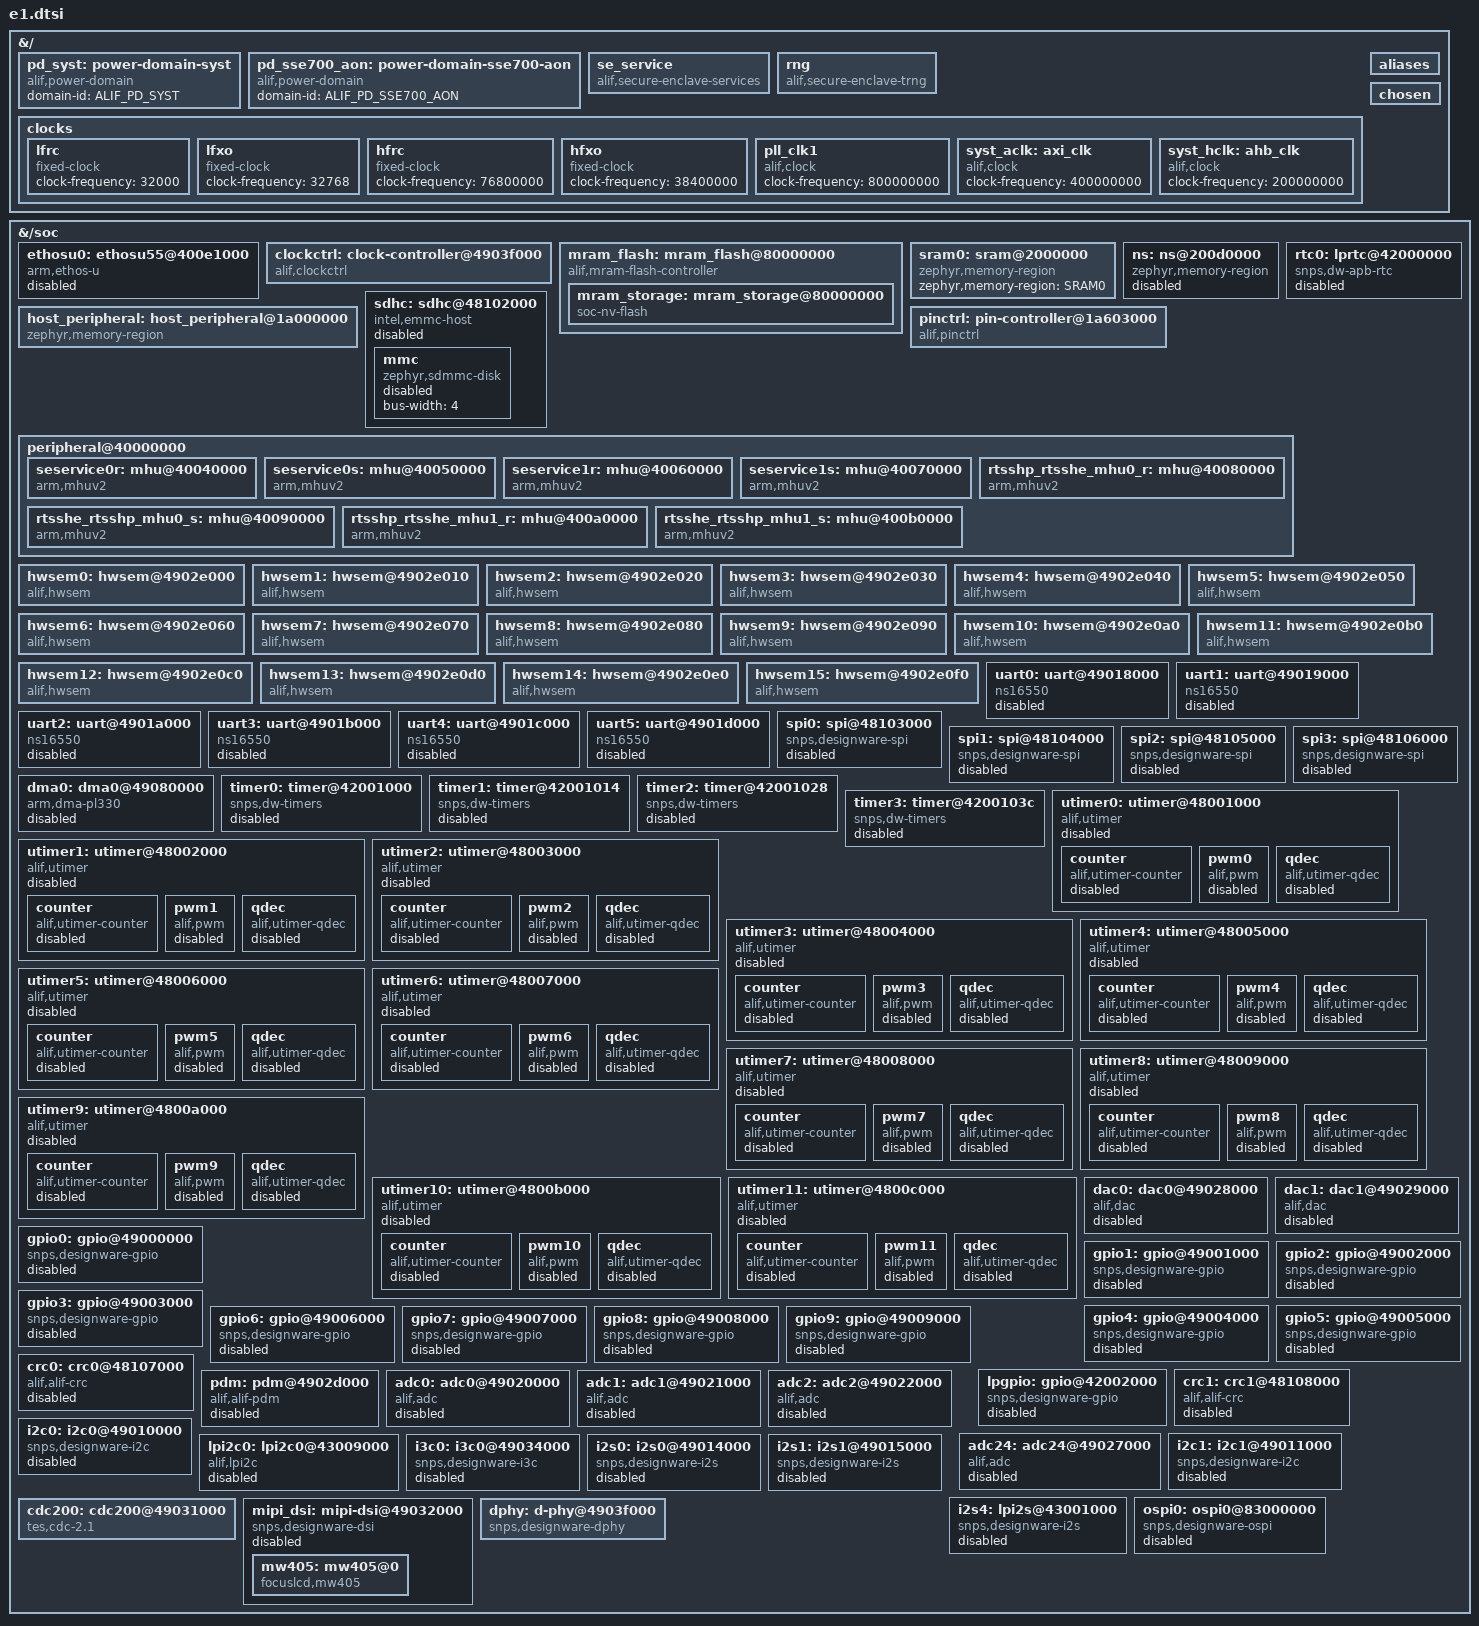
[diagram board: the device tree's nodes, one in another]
/* Copyright (c) 2025 Alif Semiconductor
 *
 * SPDX-License-Identifier: Apache-2.0
 */

#include <arm/armv8.1-m.dtsi>
#include <mem.h>
#include <zephyr/dt-bindings/gpio/gpio.h>
#include <zephyr/dt-bindings/timer/alif_utimer.h>
#include <zephyr/dt-bindings/adc/adc_alif.h>
#include <zephyr/dt-bindings/pwm/pwm.h>
#include <zephyr/dt-bindings/i2c/i2c.h>
#include <alif/common/alif_common.dtsi>
#include <zephyr/dt-bindings/mipi_dsi/mipi_dsi.h>
#include <zephyr/dt-bindings/power-domain/alif_power_domain.h>

&{/} {
	/* Individual power domain devices - one per domain */
	pd_syst: power-domain-syst {
		compatible = "alif,power-domain";
		domain-id = <ALIF_PD_SYST>;
		#power-domain-cells = <0>;
		status = "okay";
	};

	pd_sse700_aon: power-domain-sse700-aon {
		compatible = "alif,power-domain";
		domain-id = <ALIF_PD_SSE700_AON>;
		#power-domain-cells = <0>;
		status = "okay";
	};
};

&{/soc} {

	ethosu0: ethosu55@400e1000 {
		compatible = "arm,ethos-u";
		reg = <0x400e1000 0x1000>;
		interrupts = <55 0>;
		interrupt-parent = <&nvic>;
		secure-enable;
		privilege-enable;
		status = "disabled";
	};

	clockctrl: clock-controller@4903f000 {
		compatible = "alif,clockctrl";
		reg = <0x4903F000 0xB0
			0x4902F000 0xBC
			0x1A604000 0x44
			0x1A609000 0x14
			0x43007000 0x2C
			0x400F0000 0x14>;
		reg-names = "clkctl_per_mst",
			    "clkctl_per_slv",
			    "aon",
			    "vbat",
			    "m55he_cfg",
			    "m55hp_cfg";
		#clock-cells = <1>;
		status = "okay";
	};

	mram_flash: mram_flash@80000000 {
		compatible = "alif,mram-flash-controller";
		#address-cells = <1>;
		#size-cells = <1>;

		mram_storage: mram_storage@80000000 {
			compatible = "soc-nv-flash";
			erase-block-size = <1024>;
			write-block-size = <16>;
		};
	};

	sram0: sram@2000000 {
		compatible = "zephyr,memory-region","mmio-sram";
		zephyr,memory-region = "SRAM0";
	};

	ns: ns@200d0000 {
		compatible = "zephyr,memory-region";
		/* Ensemble TGU Block Size(16KB) Aligned always */
		reg = <0x200d0000 DT_SIZE_K(176)>;
		zephyr,memory-region = "NON_SECURE0";
		status = "disabled";
	};

	host_peripheral: host_peripheral@1a000000 {
		compatible = "zephyr,memory-region";
		zephyr,memory-region = "HOST_PERIPHERAL";
		reg = <0x1A000000 DT_SIZE_K(16384)>;
	};

	pinctrl: pin-controller@1a603000 {
		compatible = "alif,pinctrl";
		reg = <0x1A603000 0x00001000>, <0x42007000 0x00001000>;
		reg-names = "pinctrl", "lpgpio_pinctrl";
	};

	rtc0: lprtc@42000000 {
		compatible = "snps,dw-apb-rtc";
		reg = <0x42000000 0x1000>;
		interrupts = <58 ALIF_DEFAULT_IRQ_PRIORITY>;
		clock-frequency = <32768>;
		prescaler = <0>;
		load-value = <0>;
		status = "disabled";
	};

	sdhc: sdhc@48102000 {
		compatible = "intel,emmc-host";
		reg = <0x48102000 0xF70>;
		interrupt-parent = <&nvic>;
		interrupts = <102 ALIF_DEFAULT_IRQ_PRIORITY>;
		max-bus-freq = <25000000U>;
		min-bus-freq = <400000>;
		power-delay-ms = <500>;
		pinctrl-0 = <&pinctrl_sdmmc>;
		pinctrl-names = "default";
		mmc {
			compatible = "zephyr,sdmmc-disk";
			bus-width = <4>;
			status = "disabled";
		};
		status = "disabled";
	};

	peripheral@40000000 {
		#address-cells = < 0x1 >;
		#size-cells = < 0x1 >;
		ranges = < 0x0 0x40000000 0x2000000 >;

		seservice0r: mhu@40040000 {
			compatible = "arm,mhuv2";
			reg = < 0x40040000 0x1000 >;
			interrupts = < 37 ALIF_DEFAULT_IRQ_PRIORITY >;
			interrupt-names = "rx";
		};

		seservice0s: mhu@40050000 {
			compatible = "arm,mhuv2";
			reg = < 0x40050000 0x1000 >;
			interrupts = < 38 ALIF_DEFAULT_IRQ_PRIORITY >;
			interrupt-names = "tx";
		};

		seservice1r: mhu@40060000 {
			compatible = "arm,mhuv2";
			reg = < 0x40060000 0x1000 >;
			interrupts = < 39 ALIF_DEFAULT_IRQ_PRIORITY >;
			interrupt-names = "rx";
		};

		seservice1s: mhu@40070000 {
			compatible = "arm,mhuv2";
			reg = < 0x40070000 0x1000 >;
			interrupts = < 40 ALIF_DEFAULT_IRQ_PRIORITY >;
			interrupt-names = "tx";
		};

		rtsshp_rtsshe_mhu0_r: mhu@40080000 {
			compatible = "arm,mhuv2";
			reg = < 0x40080000 0x1000 >;
			interrupts = < 41 ALIF_DEFAULT_IRQ_PRIORITY >;
			interrupt-names = "rx";
		};

		rtsshe_rtsshp_mhu0_s: mhu@40090000 {
			compatible = "arm,mhuv2";
			reg = < 0x40090000 0x1000 >;
			interrupts = < 42 ALIF_DEFAULT_IRQ_PRIORITY >;
			interrupt-names = "tx";
		};

		rtsshp_rtsshe_mhu1_r: mhu@400a0000 {
			compatible = "arm,mhuv2";
			reg = < 0x400A0000 0x1000 >;
			interrupts = < 43 ALIF_DEFAULT_IRQ_PRIORITY >;
			interrupt-names = "rx";
		};

		rtsshe_rtsshp_mhu1_s: mhu@400b0000 {
			compatible = "arm,mhuv2";
			reg = < 0x400B0000 0x1000 >;
			interrupts = < 44 ALIF_DEFAULT_IRQ_PRIORITY >;
			interrupt-names = "tx";
		};
	};

	hwsem0: hwsem@4902e000 {
		compatible = "alif,hwsem";
		reg = <0x4902E000 0x10>;
		interrupts = < 105 ALIF_DEFAULT_IRQ_PRIORITY >;
	};

	hwsem1: hwsem@4902e010 {
		compatible = "alif,hwsem";
		reg = <0x4902E010 0x10>;
		interrupts = < 106 ALIF_DEFAULT_IRQ_PRIORITY >;
	};

	hwsem2: hwsem@4902e020 {
		compatible = "alif,hwsem";
		reg = <0x4902E020 0x10>;
		interrupts = < 107 ALIF_DEFAULT_IRQ_PRIORITY >;
	};

	hwsem3: hwsem@4902e030 {
		compatible = "alif,hwsem";
		reg = <0x4902E030 0x10>;
		interrupts = < 108 ALIF_DEFAULT_IRQ_PRIORITY >;
	};

	hwsem4: hwsem@4902e040 {
		compatible = "alif,hwsem";
		reg = <0x4902E040 0x10>;
		interrupts = < 109 ALIF_DEFAULT_IRQ_PRIORITY >;
	};

	hwsem5: hwsem@4902e050 {
		compatible = "alif,hwsem";
		reg = <0x4902E050 0x10>;
		interrupts = < 110 ALIF_DEFAULT_IRQ_PRIORITY >;
	};

	hwsem6: hwsem@4902e060 {
		compatible = "alif,hwsem";
		reg = <0x4902E060 0x10>;
		interrupts = < 111 ALIF_DEFAULT_IRQ_PRIORITY >;
	};

	hwsem7: hwsem@4902e070 {
		compatible = "alif,hwsem";
		reg = <0x4902E070 0x10>;
		interrupts = < 112 ALIF_DEFAULT_IRQ_PRIORITY >;
	};

	hwsem8: hwsem@4902e080 {
		compatible = "alif,hwsem";
		reg = <0x4902E080 0x10>;
		interrupts = < 113 ALIF_DEFAULT_IRQ_PRIORITY >;
	};

	hwsem9: hwsem@4902e090 {
		compatible = "alif,hwsem";
		reg = <0x4902E090 0x10>;
		interrupts = < 114 ALIF_DEFAULT_IRQ_PRIORITY >;
	};

	hwsem10: hwsem@4902e0a0 {
		compatible = "alif,hwsem";
		reg = <0x4902E0A0 0x10>;
		interrupts = < 115 ALIF_DEFAULT_IRQ_PRIORITY >;
	};

	hwsem11: hwsem@4902e0b0 {
		compatible = "alif,hwsem";
		reg = <0x4902E0B0 0x10>;
		interrupts = < 116 ALIF_DEFAULT_IRQ_PRIORITY >;
	};

	hwsem12: hwsem@4902e0c0 {
		compatible = "alif,hwsem";
		reg = <0x4902E0C0 0x10>;
		interrupts = < 117 ALIF_DEFAULT_IRQ_PRIORITY >;
	};

	hwsem13: hwsem@4902e0d0 {
		compatible = "alif,hwsem";
		reg = <0x4902E0D0 0x10>;
		interrupts = < 118 ALIF_DEFAULT_IRQ_PRIORITY >;
	};

	hwsem14: hwsem@4902e0e0 {
		compatible = "alif,hwsem";
		reg = <0x4902E0E0 0x10>;
		interrupts = < 119 ALIF_DEFAULT_IRQ_PRIORITY >;
	};

	hwsem15: hwsem@4902e0f0 {
		compatible = "alif,hwsem";
		reg = <0x4902E0F0 0x10>;
		interrupts = < 120 ALIF_DEFAULT_IRQ_PRIORITY >;
	};

	uart0: uart@49018000 {
		compatible = "ns16550";
		reg = <0x49018000 0x100>;
		clocks = <&clockctrl ALIF_UART0_SYST_PCLK>;
		interrupts = <124 ALIF_DEFAULT_IRQ_PRIORITY>;
		power-domains = <&pd_syst>;
		reg-shift = <2>;
		current-speed = <115200>;
		dlf = <4>;
		pinctrl-0 = <&pinctrl_uart0>;
		pinctrl-1 = <&pinctrl_uart0_sleep>;
		pinctrl-names = "default", "sleep";
		fifo-size = <32>;
		status = "disabled";
	};

	uart1: uart@49019000 {
		compatible = "ns16550";
		reg = <0x49019000 0x100>;
		clocks = <&clockctrl ALIF_UART1_SYST_PCLK>;
		interrupts = <125 ALIF_DEFAULT_IRQ_PRIORITY>;
		power-domains = <&pd_syst>;
		reg-shift = <2>;
		current-speed = <115200>;
		dlf = <4>;
		pinctrl-0 = <&pinctrl_uart1>;
		pinctrl-1 = <&pinctrl_uart1_sleep>;
		pinctrl-names = "default", "sleep";
		fifo-size = <32>;
		status = "disabled";
	};

	uart2: uart@4901a000 {
		compatible = "ns16550";
		reg = <0x4901a000 0x100>;
		clocks = <&clockctrl ALIF_UART2_SYST_PCLK>;
		interrupts = <126 ALIF_DEFAULT_IRQ_PRIORITY>;
		power-domains = <&pd_syst>;
		reg-shift = <2>;
		current-speed = <115200>;
		dlf = <4>;
		pinctrl-0 = <&pinctrl_uart2>;
		pinctrl-1 = <&pinctrl_uart2_sleep>;
		pinctrl-names = "default", "sleep";
		fifo-size = <32>;
		status = "disabled";
	};

	uart3: uart@4901b000 {
		compatible = "ns16550";
		reg = <0x4901b000 0x100>;
		clocks = <&clockctrl ALIF_UART3_SYST_PCLK>;
		interrupts = <127 ALIF_DEFAULT_IRQ_PRIORITY>;
		power-domains = <&pd_syst>;
		reg-shift = <2>;
		current-speed = <115200>;
		dlf = <4>;
		pinctrl-0 = <&pinctrl_uart3>;
		pinctrl-1 = <&pinctrl_uart3_sleep>;
		pinctrl-names = "default", "sleep";
		fifo-size = <32>;
		status = "disabled";
	};

	uart4: uart@4901c000 {
		compatible = "ns16550";
		reg = <0x4901c000 0x100>;
		clocks = <&clockctrl ALIF_UART4_SYST_PCLK>;
		interrupts = <128 ALIF_DEFAULT_IRQ_PRIORITY>;
		power-domains = <&pd_syst>;
		reg-shift = <2>;
		current-speed = <115200>;
		dlf = <4>;
		pinctrl-0 = <&pinctrl_uart4>;
		pinctrl-1 = <&pinctrl_uart4_sleep>;
		pinctrl-names = "default", "sleep";
		fifo-size = <32>;
		status = "disabled";
	};

	uart5: uart@4901d000 {
		compatible = "ns16550";
		reg = <0x4901d000 0x100>;
		clocks = <&clockctrl ALIF_UART5_SYST_PCLK>;
		interrupts = <129 ALIF_DEFAULT_IRQ_PRIORITY>;
		power-domains = <&pd_syst>;
		reg-shift = <2>;
		current-speed = <115200>;
		dlf = <4>;
		pinctrl-0 = <&pinctrl_uart5>;
		pinctrl-1 = <&pinctrl_uart5_sleep>;
		pinctrl-names = "default", "sleep";
		fifo-size = <32>;
		status = "disabled";
	};

	spi0: spi@48103000 {
		dwc-ssi;
		compatible = "snps,designware-spi";
		#address-cells = <1>;
		#size-cells = <0>;
		pinctrl-0 = < &pinctrl_spi0 >;
		pinctrl-names = "default";
		reg = <0x48103000 0x1000>;
		interrupt-parent = <&nvic>;
		interrupts = <137 ALIF_DEFAULT_IRQ_PRIORITY>;
		clocks = <&syst_hclk>;
		fifo-depth = <16>;
		max-xfer-size = <32>;
		rx-delay = <4>;
		status = "disabled";
	};

	spi1: spi@48104000 {
		dwc-ssi;
		compatible = "snps,designware-spi";
		#address-cells = <1>;
		#size-cells = <0>;
		pinctrl-0 = < &pinctrl_spi1 >;
		pinctrl-names = "default";
		reg = <0x48104000 0x1000>;
		interrupt-parent = <&nvic>;
		interrupts = <138 ALIF_DEFAULT_IRQ_PRIORITY>;
		clocks = <&syst_hclk>;
		fifo-depth = <16>;
		max-xfer-size = <32>;
		rx-delay = <4>;
		status = "disabled";
	};

	spi2: spi@48105000 {
		dwc-ssi;
		compatible = "snps,designware-spi";
		#address-cells = <1>;
		#size-cells = <0>;
		pinctrl-0 = < &pinctrl_spi2 >;
		pinctrl-names = "default";
		reg = <0x48105000 0x1000>;
		interrupt-parent = <&nvic>;
		interrupts = <139 ALIF_DEFAULT_IRQ_PRIORITY>;
		clocks = <&syst_hclk>;
		fifo-depth = <16>;
		max-xfer-size = <32>;
		rx-delay = <4>;
		status = "disabled";
	};

	spi3: spi@48106000 {
		dwc-ssi;
		compatible = "snps,designware-spi";
		#address-cells = <1>;
		#size-cells = <0>;
		pinctrl-0 = < &pinctrl_spi3 >;
		pinctrl-names = "default";
		reg = <0x48106000 0x1000>;
		interrupt-parent = <&nvic>;
		interrupts = <140 ALIF_DEFAULT_IRQ_PRIORITY>;
		clocks = <&syst_hclk>;
		fifo-depth = <16>;
		max-xfer-size = <32>;
		rx-delay = <4>;
		status = "disabled";
	};

	dma0: dma0@49080000 {
		compatible = "arm,dma-pl330";
		reg = <0x49080000 0x1000>;
		reg-names = "pl330_regs";
		dma-channels = <4>;
		#dma-cells = <2>;
		interrupt-parent = <&nvic>;
		interrupts = <299 ALIF_DEFAULT_IRQ_PRIORITY>,
			     <300 ALIF_DEFAULT_IRQ_PRIORITY>,
			     <301 ALIF_DEFAULT_IRQ_PRIORITY>,
			     <302 ALIF_DEFAULT_IRQ_PRIORITY>,
			     <331 ALIF_DEFAULT_IRQ_PRIORITY>;
		interrupt-names = "channel0", "channel1",
						  "channel2", "channel3",
						  "abort";
		status = "disabled";
	};
	timer0: timer@42001000 {
		compatible = "snps,dw-timers";
		reg = <0x42001000 0x14>;
		interrupts = <60 ALIF_DEFAULT_IRQ_PRIORITY>;
		clocks = <&clockctrl ALIF_LPTIMER0_S32K_CLK>;
		status = "disabled";
	};

	timer1: timer@42001014 {
		compatible = "snps,dw-timers";
		reg = <0x42001014 0x14>;
		interrupts = <61 ALIF_DEFAULT_IRQ_PRIORITY>;
		clocks = <&clockctrl ALIF_LPTIMER1_S32K_CLK>;
		status = "disabled";
	};

	timer2: timer@42001028 {
		compatible = "snps,dw-timers";
		reg = <0x42001028 0x14>;
		interrupts = <62 ALIF_DEFAULT_IRQ_PRIORITY>;
		clocks = <&clockctrl ALIF_LPTIMER2_S32K_CLK>;
		status = "disabled";
	};

	timer3: timer@4200103c {
		compatible = "snps,dw-timers";
		reg = <0x4200103C 0x14>;
		interrupts = <63 ALIF_DEFAULT_IRQ_PRIORITY>;
		clocks = <&clockctrl ALIF_LPTIMER3_S32K_CLK>;
		status = "disabled";
	};

	utimer0: utimer@48001000 {
		compatible = "alif,utimer";
		reg = <0x48001000 0x1000 0x48000000 0x24>;
		reg-names = "timer", "global";
		interrupts = <377 ALIF_DEFAULT_IRQ_PRIORITY>,
			     <378 ALIF_DEFAULT_IRQ_PRIORITY>,
			     <379 ALIF_DEFAULT_IRQ_PRIORITY>,
			     <380 ALIF_DEFAULT_IRQ_PRIORITY>,
			     <381 ALIF_DEFAULT_IRQ_PRIORITY>,
			     <382 ALIF_DEFAULT_IRQ_PRIORITY>,
			     <383 ALIF_DEFAULT_IRQ_PRIORITY>,
			     <384 ALIF_DEFAULT_IRQ_PRIORITY>;
		interrupt-names = "comp_capt_a", "comp_capt_b",
				"comp_a_buf1", "comp_a_buf2", "comp_b_buf1",
				"comp_b_buf2", "underflow", "overflow";
		timer-id = <0>;
		clocks = <&clockctrl ALIF_UTIMER_CLK>;
		counter-direction = < ALIF_UTIMER_COUNTER_DIRECTION_UP >;
		status = "disabled";

		counter {
			compatible = "alif,utimer-counter";
			status = "disabled";
		};

		pwm0 {
			compatible = "alif,pwm";
			#pwm-cells = <3>;
			status = "disabled";
		};

		qdec {
			compatible = "alif,utimer-qdec";
			counts-per-revolution = <1000>;
			input-filter-enable;
			filter-prescaler = <16>;
			filter-taps = <1>;
			status = "disabled";
		};
	};

	utimer1: utimer@48002000 {
		compatible = "alif,utimer";
		reg = <0x48002000 0x1000 0x48000000 0x24>;
		reg-names = "timer", "global";
		interrupts = <385 ALIF_DEFAULT_IRQ_PRIORITY>,
			     <386 ALIF_DEFAULT_IRQ_PRIORITY>,
			     <387 ALIF_DEFAULT_IRQ_PRIORITY>,
			     <388 ALIF_DEFAULT_IRQ_PRIORITY>,
			     <389 ALIF_DEFAULT_IRQ_PRIORITY>,
			     <390 ALIF_DEFAULT_IRQ_PRIORITY>,
			     <391 ALIF_DEFAULT_IRQ_PRIORITY>,
			     <392 ALIF_DEFAULT_IRQ_PRIORITY>;
		interrupt-names = "comp_capt_a", "comp_capt_b",
				"comp_a_buf1", "comp_a_buf2", "comp_b_buf1",
				"comp_b_buf2", "underflow", "overflow";
		timer-id = <1>;
		clocks = <&clockctrl ALIF_UTIMER_CLK>;
		counter-direction = < ALIF_UTIMER_COUNTER_DIRECTION_UP >;
		status = "disabled";

		counter {
			compatible = "alif,utimer-counter";
			status = "disabled";
		};

		pwm1 {
			compatible = "alif,pwm";
			#pwm-cells = <3>;
			status = "disabled";
		};

		qdec {
			compatible = "alif,utimer-qdec";
			counts-per-revolution = <1000>;
			input-filter-enable;
			filter-prescaler = <16>;
			filter-taps = <1>;
			status = "disabled";
		};
	};

	utimer2: utimer@48003000 {
		compatible = "alif,utimer";
		reg = <0x48003000 0x1000 0x48000000 0x24>;
		reg-names = "timer", "global";
		interrupts = <393 ALIF_DEFAULT_IRQ_PRIORITY>,
			     <394 ALIF_DEFAULT_IRQ_PRIORITY>,
			     <395 ALIF_DEFAULT_IRQ_PRIORITY>,
			     <396 ALIF_DEFAULT_IRQ_PRIORITY>,
			     <397 ALIF_DEFAULT_IRQ_PRIORITY>,
			     <398 ALIF_DEFAULT_IRQ_PRIORITY>,
			     <399 ALIF_DEFAULT_IRQ_PRIORITY>,
			     <400 ALIF_DEFAULT_IRQ_PRIORITY>;
		interrupt-names = "comp_capt_a", "comp_capt_b",
				"comp_a_buf1", "comp_a_buf2", "comp_b_buf1",
				"comp_b_buf2", "underflow", "overflow";
		timer-id = <2>;
		clocks = <&clockctrl ALIF_UTIMER_CLK>;
		counter-direction = < ALIF_UTIMER_COUNTER_DIRECTION_UP >;
		status = "disabled";

		counter {
			compatible = "alif,utimer-counter";
			status = "disabled";
		};

		pwm2 {
			compatible = "alif,pwm";
			#pwm-cells = <3>;
			status = "disabled";
		};

		qdec {
			compatible = "alif,utimer-qdec";
			counts-per-revolution = <1000>;
			input-filter-enable;
			filter-prescaler = <16>;
			filter-taps = <1>;
			status = "disabled";
		};
	};

	utimer3: utimer@48004000 {
		compatible = "alif,utimer";
		reg = <0x48004000 0x1000 0x48000000 0x24>;
		reg-names = "timer", "global";
		interrupts = <401 ALIF_DEFAULT_IRQ_PRIORITY>,
			     <402 ALIF_DEFAULT_IRQ_PRIORITY>,
			     <403 ALIF_DEFAULT_IRQ_PRIORITY>,
			     <404 ALIF_DEFAULT_IRQ_PRIORITY>,
			     <405 ALIF_DEFAULT_IRQ_PRIORITY>,
			     <406 ALIF_DEFAULT_IRQ_PRIORITY>,
			     <407 ALIF_DEFAULT_IRQ_PRIORITY>,
			     <408 ALIF_DEFAULT_IRQ_PRIORITY>;
		interrupt-names = "comp_capt_a", "comp_capt_b",
				"comp_a_buf1", "comp_a_buf2", "comp_b_buf1",
				"comp_b_buf2", "underflow", "overflow";
		timer-id = <3>;
		clocks = <&clockctrl ALIF_UTIMER_CLK>;
		counter-direction = < ALIF_UTIMER_COUNTER_DIRECTION_UP >;
		status = "disabled";

		counter {
			compatible = "alif,utimer-counter";
			status = "disabled";
		};

		pwm3 {
			compatible = "alif,pwm";
			#pwm-cells = <3>;
			status = "disabled";
		};

		qdec {
			compatible = "alif,utimer-qdec";
			counts-per-revolution = <1000>;
			input-filter-enable;
			filter-prescaler = <16>;
			filter-taps = <1>;
			status = "disabled";
		};
	};

	utimer4: utimer@48005000 {
		compatible = "alif,utimer";
		reg = <0x48005000 0x1000 0x48000000 0x24>;
		reg-names = "timer", "global";
		interrupts = <409 ALIF_DEFAULT_IRQ_PRIORITY>,
			     <410 ALIF_DEFAULT_IRQ_PRIORITY>,
			     <411 ALIF_DEFAULT_IRQ_PRIORITY>,
			     <412 ALIF_DEFAULT_IRQ_PRIORITY>,
			     <413 ALIF_DEFAULT_IRQ_PRIORITY>,
			     <414 ALIF_DEFAULT_IRQ_PRIORITY>,
			     <415 ALIF_DEFAULT_IRQ_PRIORITY>,
			     <416 ALIF_DEFAULT_IRQ_PRIORITY>;
		interrupt-names = "comp_capt_a", "comp_capt_b",
				"comp_a_buf1", "comp_a_buf2", "comp_b_buf1",
				"comp_b_buf2", "underflow", "overflow";
		timer-id = <4>;
		clocks = <&clockctrl ALIF_UTIMER_CLK>;
		counter-direction = < ALIF_UTIMER_COUNTER_DIRECTION_UP >;
		status = "disabled";

		counter {
			compatible = "alif,utimer-counter";
			status = "disabled";
		};

		pwm4 {
			compatible = "alif,pwm";
			#pwm-cells = <3>;
			status = "disabled";
		};

		qdec {
			compatible = "alif,utimer-qdec";
			counts-per-revolution = <1000>;
			input-filter-enable;
			filter-prescaler = <16>;
			filter-taps = <1>;
			status = "disabled";
		};
	};

	utimer5: utimer@48006000 {
		compatible = "alif,utimer";
		reg = <0x48006000 0x1000 0x48000000 0x24>;
		reg-names = "timer", "global";
		interrupts = <417 ALIF_DEFAULT_IRQ_PRIORITY>,
			     <418 ALIF_DEFAULT_IRQ_PRIORITY>,
			     <419 ALIF_DEFAULT_IRQ_PRIORITY>,
			     <420 ALIF_DEFAULT_IRQ_PRIORITY>,
			     <421 ALIF_DEFAULT_IRQ_PRIORITY>,
			     <422 ALIF_DEFAULT_IRQ_PRIORITY>,
			     <423 ALIF_DEFAULT_IRQ_PRIORITY>,
			     <424 ALIF_DEFAULT_IRQ_PRIORITY>;
		interrupt-names = "comp_capt_a", "comp_capt_b",
				"comp_a_buf1", "comp_a_buf2", "comp_b_buf1",
				"comp_b_buf2", "underflow", "overflow";
		timer-id = <5>;
		clocks = <&clockctrl ALIF_UTIMER_CLK>;
		counter-direction = < ALIF_UTIMER_COUNTER_DIRECTION_UP >;
		status = "disabled";

		counter {
			compatible = "alif,utimer-counter";
			status = "disabled";
		};

		pwm5 {
			compatible = "alif,pwm";
			#pwm-cells = <3>;
			status = "disabled";
		};

		qdec {
			compatible = "alif,utimer-qdec";
			counts-per-revolution = <1000>;
			input-filter-enable;
			filter-prescaler = <16>;
			filter-taps = <1>;
			status = "disabled";
		};
	};

	utimer6: utimer@48007000 {
		compatible = "alif,utimer";
		reg = <0x48007000 0x1000 0x48000000 0x24>;
		reg-names = "timer", "global";
		interrupts = <425 ALIF_DEFAULT_IRQ_PRIORITY>,
			     <426 ALIF_DEFAULT_IRQ_PRIORITY>,
			     <427 ALIF_DEFAULT_IRQ_PRIORITY>,
			     <428 ALIF_DEFAULT_IRQ_PRIORITY>,
			     <429 ALIF_DEFAULT_IRQ_PRIORITY>,
			     <430 ALIF_DEFAULT_IRQ_PRIORITY>,
			     <431 ALIF_DEFAULT_IRQ_PRIORITY>,
			     <432 ALIF_DEFAULT_IRQ_PRIORITY>;
		interrupt-names = "comp_capt_a", "comp_capt_b",
				"comp_a_buf1", "comp_a_buf2", "comp_b_buf1",
				"comp_b_buf2", "underflow", "overflow";
		timer-id = <6>;
		clocks = <&clockctrl ALIF_UTIMER_CLK>;
		counter-direction = < ALIF_UTIMER_COUNTER_DIRECTION_UP >;
		status = "disabled";

		counter {
			compatible = "alif,utimer-counter";
			status = "disabled";
		};

		pwm6 {
			compatible = "alif,pwm";
			#pwm-cells = <3>;
			status = "disabled";
		};

		qdec {
			compatible = "alif,utimer-qdec";
			counts-per-revolution = <1000>;
			input-filter-enable;
			filter-prescaler = <16>;
			filter-taps = <1>;
			status = "disabled";
		};
	};

	utimer7: utimer@48008000 {
		compatible = "alif,utimer";
		reg = <0x48008000 0x1000 0x48000000 0x24>;
		reg-names = "timer", "global";
		interrupts = <433 ALIF_DEFAULT_IRQ_PRIORITY>,
			     <434 ALIF_DEFAULT_IRQ_PRIORITY>,
			     <435 ALIF_DEFAULT_IRQ_PRIORITY>,
			     <436 ALIF_DEFAULT_IRQ_PRIORITY>,
			     <437 ALIF_DEFAULT_IRQ_PRIORITY>,
			     <438 ALIF_DEFAULT_IRQ_PRIORITY>,
			     <439 ALIF_DEFAULT_IRQ_PRIORITY>,
			     <440 ALIF_DEFAULT_IRQ_PRIORITY>;
		interrupt-names = "comp_capt_a", "comp_capt_b",
				"comp_a_buf1", "comp_a_buf2", "comp_b_buf1",
				"comp_b_buf2", "underflow", "overflow";
		timer-id = <7>;
		clocks = <&clockctrl ALIF_UTIMER_CLK>;
		counter-direction = < ALIF_UTIMER_COUNTER_DIRECTION_UP >;
		status = "disabled";

		counter {
			compatible = "alif,utimer-counter";
			status = "disabled";
		};

		pwm7 {
			compatible = "alif,pwm";
			#pwm-cells = <3>;
			status = "disabled";
		};

		qdec {
			compatible = "alif,utimer-qdec";
			counts-per-revolution = <1000>;
			input-filter-enable;
			filter-prescaler = <16>;
			filter-taps = <1>;
			status = "disabled";
		};
	};

	utimer8: utimer@48009000 {
		compatible = "alif,utimer";
		reg = <0x48009000 0x1000 0x48000000 0x24>;
		reg-names = "timer", "global";
		interrupts = <441 ALIF_DEFAULT_IRQ_PRIORITY>,
			     <442 ALIF_DEFAULT_IRQ_PRIORITY>,
			     <443 ALIF_DEFAULT_IRQ_PRIORITY>,
			     <444 ALIF_DEFAULT_IRQ_PRIORITY>,
			     <445 ALIF_DEFAULT_IRQ_PRIORITY>,
			     <446 ALIF_DEFAULT_IRQ_PRIORITY>,
			     <447 ALIF_DEFAULT_IRQ_PRIORITY>,
			     <448 ALIF_DEFAULT_IRQ_PRIORITY>;
		interrupt-names = "comp_capt_a", "comp_capt_b",
				"comp_a_buf1", "comp_a_buf2", "comp_b_buf1",
				"comp_b_buf2", "underflow", "overflow";
		timer-id = <8>;
		clocks = <&clockctrl ALIF_UTIMER_CLK>;
		counter-direction = < ALIF_UTIMER_COUNTER_DIRECTION_UP >;
		status = "disabled";

		counter {
			compatible = "alif,utimer-counter";
			status = "disabled";
		};

		pwm8 {
			compatible = "alif,pwm";
			#pwm-cells = <3>;
			status = "disabled";
		};

		qdec {
			compatible = "alif,utimer-qdec";
			counts-per-revolution = <1000>;
			input-filter-enable;
			filter-prescaler = <16>;
			filter-taps = <1>;
			status = "disabled";
		};
	};

	utimer9: utimer@4800a000 {
		compatible = "alif,utimer";
		reg = <0x4800A000 0x1000 0x48000000 0x24>;
		reg-names = "timer", "global";
		interrupts = <449 ALIF_DEFAULT_IRQ_PRIORITY>,
			     <450 ALIF_DEFAULT_IRQ_PRIORITY>,
			     <451 ALIF_DEFAULT_IRQ_PRIORITY>,
			     <452 ALIF_DEFAULT_IRQ_PRIORITY>,
			     <453 ALIF_DEFAULT_IRQ_PRIORITY>,
			     <454 ALIF_DEFAULT_IRQ_PRIORITY>,
			     <455 ALIF_DEFAULT_IRQ_PRIORITY>,
			     <456 ALIF_DEFAULT_IRQ_PRIORITY>;
		interrupt-names = "comp_capt_a", "comp_capt_b",
				"comp_a_buf1", "comp_a_buf2", "comp_b_buf1",
				"comp_b_buf2", "underflow", "overflow";
		timer-id = <9>;
		clocks = <&clockctrl ALIF_UTIMER_CLK>;
		counter-direction = < ALIF_UTIMER_COUNTER_DIRECTION_UP >;
		status = "disabled";

		counter {
			compatible = "alif,utimer-counter";
			status = "disabled";
		};

		pwm9 {
			compatible = "alif,pwm";
			#pwm-cells = <3>;
			status = "disabled";
		};

		qdec {
			compatible = "alif,utimer-qdec";
			counts-per-revolution = <1000>;
			input-filter-enable;
			filter-prescaler = <16>;
			filter-taps = <1>;
			status = "disabled";
		};
	};

	utimer10: utimer@4800b000 {
		compatible = "alif,utimer";
		reg = <0x4800B000 0x1000 0x48000000 0x24>;
		reg-names = "timer", "global";
		interrupts = <457 ALIF_DEFAULT_IRQ_PRIORITY>,
			     <458 ALIF_DEFAULT_IRQ_PRIORITY>,
			     <459 ALIF_DEFAULT_IRQ_PRIORITY>,
			     <460 ALIF_DEFAULT_IRQ_PRIORITY>,
			     <461 ALIF_DEFAULT_IRQ_PRIORITY>,
			     <462 ALIF_DEFAULT_IRQ_PRIORITY>,
			     <463 ALIF_DEFAULT_IRQ_PRIORITY>,
			     <464 ALIF_DEFAULT_IRQ_PRIORITY>;
		interrupt-names = "comp_capt_a", "comp_capt_b",
				"comp_a_buf1", "comp_a_buf2", "comp_b_buf1",
				"comp_b_buf2", "underflow", "overflow";
		timer-id = <10>;
		clocks = <&clockctrl ALIF_UTIMER_CLK>;
		counter-direction = < ALIF_UTIMER_COUNTER_DIRECTION_UP >;
		status = "disabled";

		counter {
			compatible = "alif,utimer-counter";
			status = "disabled";
		};

		pwm10 {
			compatible = "alif,pwm";
			#pwm-cells = <3>;
			status = "disabled";
		};

		qdec {
			compatible = "alif,utimer-qdec";
			counts-per-revolution = <1000>;
			input-filter-enable;
			filter-prescaler = <16>;
			filter-taps = <1>;
			status = "disabled";
		};
	};

	utimer11: utimer@4800c000 {
		compatible = "alif,utimer";
		reg = <0x4800C000 0x1000 0x48000000 0x24>;
		reg-names = "timer", "global";
		interrupts = <465 ALIF_DEFAULT_IRQ_PRIORITY>,
			     <466 ALIF_DEFAULT_IRQ_PRIORITY>,
			     <467 ALIF_DEFAULT_IRQ_PRIORITY>,
			     <468 ALIF_DEFAULT_IRQ_PRIORITY>,
			     <469 ALIF_DEFAULT_IRQ_PRIORITY>,
			     <470 ALIF_DEFAULT_IRQ_PRIORITY>,
			     <471 ALIF_DEFAULT_IRQ_PRIORITY>,
			     <472 ALIF_DEFAULT_IRQ_PRIORITY>;
		interrupt-names = "comp_capt_a", "comp_capt_b",
				"comp_a_buf1", "comp_a_buf2", "comp_b_buf1",
				"comp_b_buf2", "underflow", "overflow";
		timer-id = <11>;
		clocks = <&clockctrl ALIF_UTIMER_CLK>;
		counter-direction = < ALIF_UTIMER_COUNTER_DIRECTION_UP >;
		status = "disabled";

		counter {
			compatible = "alif,utimer-counter";
			status = "disabled";
		};

		pwm11 {
			compatible = "alif,pwm";
			#pwm-cells = <3>;
			status = "disabled";
		};

		qdec {
			compatible = "alif,utimer-qdec";
			counts-per-revolution = <1000>;
			input-filter-enable;
			filter-prescaler = <16>;
			filter-taps = <1>;
			status = "disabled";
		};
	};

	dac0: dac0@49028000 {
		compatible = "alif,dac";
		reg = <0x49028000 0x1000>,
			<0x49023000 0x100>,
			<0x1A60A000 0x100>,
			<0x4902B000 0x100>;
		reg-names = "dac_reg","cmp_reg","vbat_reg","adc_vref";
		pinctrl-names = "default";
		pinctrl-0 = <&pinctrl_dac0>;
		output_current = "DAC_1200UA_OUT_CUR";
		capacitance = "DAC_8PF_CAPACITANCE";
		status = "disabled";
	};

	dac1: dac1@49029000 {
		compatible = "alif,dac";
		reg = <0x49029000 0x1000>,
			<0x49023000 0x100>,
			<0x1A60A000 0x100>,
			<0x4902B000 0x100>;
		reg-names = "dac_reg","cmp_reg","vbat_reg","adc_vref";
		pinctrl-names = "default";
		pinctrl-0 = <&pinctrl_dac1>;
		output_current = "DAC_1200UA_OUT_CUR";
		capacitance = "DAC_8PF_CAPACITANCE";
		status = "disabled";
	};

	gpio0: gpio@49000000 {
		compatible = "snps,designware-gpio";
		reg = <0x49000000 0x1000>;
		ngpios = <8>;
		interrupts = <179 ALIF_DEFAULT_IRQ_PRIORITY>,
			     <180 ALIF_DEFAULT_IRQ_PRIORITY>,
			     <181 ALIF_DEFAULT_IRQ_PRIORITY>,
			     <182 ALIF_DEFAULT_IRQ_PRIORITY>,
			     <183 ALIF_DEFAULT_IRQ_PRIORITY>,
			     <184 ALIF_DEFAULT_IRQ_PRIORITY>,
			     <185 ALIF_DEFAULT_IRQ_PRIORITY>,
			     <186 ALIF_DEFAULT_IRQ_PRIORITY>;
		pinctrl-0 = < &pinctrl_gpio0 >;
		pinctrl-names = "default";
		gpio-controller;
		#gpio-cells = <2>;
		status = "disabled";
	};

	gpio1: gpio@49001000 {
		compatible = "snps,designware-gpio";
		reg = <0x49001000 0x1000>;
		ngpios = <8>;
		interrupts = <187 ALIF_DEFAULT_IRQ_PRIORITY>,
			     <188 ALIF_DEFAULT_IRQ_PRIORITY>,
			     <189 ALIF_DEFAULT_IRQ_PRIORITY>,
			     <190 ALIF_DEFAULT_IRQ_PRIORITY>,
			     <191 ALIF_DEFAULT_IRQ_PRIORITY>,
			     <192 ALIF_DEFAULT_IRQ_PRIORITY>,
			     <193 ALIF_DEFAULT_IRQ_PRIORITY>,
			     <194 ALIF_DEFAULT_IRQ_PRIORITY>;
		pinctrl-0 = < &pinctrl_gpio1 >;
		pinctrl-names = "default";
		gpio-controller;
		#gpio-cells = <2>;
		status = "disabled";
	};

	gpio2: gpio@49002000 {
		compatible = "snps,designware-gpio";
		reg = <0x49002000 0x1000>;
		ngpios = <8>;
		interrupts = <195 ALIF_DEFAULT_IRQ_PRIORITY>,
			     <196 ALIF_DEFAULT_IRQ_PRIORITY>,
			     <197 ALIF_DEFAULT_IRQ_PRIORITY>,
			     <198 ALIF_DEFAULT_IRQ_PRIORITY>,
			     <199 ALIF_DEFAULT_IRQ_PRIORITY>,
			     <200 ALIF_DEFAULT_IRQ_PRIORITY>,
			     <201 ALIF_DEFAULT_IRQ_PRIORITY>,
			     <202 ALIF_DEFAULT_IRQ_PRIORITY>;
		pinctrl-0 = < &pinctrl_gpio2 >;
		pinctrl-names = "default";
		gpio-controller;
		#gpio-cells = <2>;
		status = "disabled";
	};

	gpio3: gpio@49003000 {
		compatible = "snps,designware-gpio";
		reg = <0x49003000 0x1000>;
		ngpios = <8>;
		interrupts = <203 ALIF_DEFAULT_IRQ_PRIORITY>,
			     <204 ALIF_DEFAULT_IRQ_PRIORITY>,
			     <205 ALIF_DEFAULT_IRQ_PRIORITY>,
			     <206 ALIF_DEFAULT_IRQ_PRIORITY>,
			     <207 ALIF_DEFAULT_IRQ_PRIORITY>,
			     <208 ALIF_DEFAULT_IRQ_PRIORITY>,
			     <209 ALIF_DEFAULT_IRQ_PRIORITY>,
			     <210 ALIF_DEFAULT_IRQ_PRIORITY>;
		pinctrl-0 = < &pinctrl_gpio3 >;
		pinctrl-names = "default";
		gpio-controller;
		#gpio-cells = <2>;
		status = "disabled";
	};

	gpio4: gpio@49004000 {
		compatible = "snps,designware-gpio";
		reg = <0x49004000 0x1000>;
		ngpios = <8>;
		interrupts = <211 ALIF_DEFAULT_IRQ_PRIORITY>,
			     <212 ALIF_DEFAULT_IRQ_PRIORITY>,
			     <213 ALIF_DEFAULT_IRQ_PRIORITY>,
			     <214 ALIF_DEFAULT_IRQ_PRIORITY>,
			     <215 ALIF_DEFAULT_IRQ_PRIORITY>,
			     <216 ALIF_DEFAULT_IRQ_PRIORITY>,
			     <217 ALIF_DEFAULT_IRQ_PRIORITY>,
			     <218 ALIF_DEFAULT_IRQ_PRIORITY>;
		pinctrl-0 = < &pinctrl_gpio4 >;
		pinctrl-names = "default";
		gpio-controller;
		#gpio-cells = <2>;
		status = "disabled";
	};

	gpio5: gpio@49005000 {
		compatible = "snps,designware-gpio";
		reg = <0x49005000 0x1000>;
		ngpios = <8>;
		interrupts = <219 ALIF_DEFAULT_IRQ_PRIORITY>,
			     <220 ALIF_DEFAULT_IRQ_PRIORITY>,
			     <221 ALIF_DEFAULT_IRQ_PRIORITY>,
			     <222 ALIF_DEFAULT_IRQ_PRIORITY>,
			     <223 ALIF_DEFAULT_IRQ_PRIORITY>,
			     <224 ALIF_DEFAULT_IRQ_PRIORITY>,
			     <225 ALIF_DEFAULT_IRQ_PRIORITY>,
			     <226 ALIF_DEFAULT_IRQ_PRIORITY>;
		pinctrl-0 = < &pinctrl_gpio5 >;
		pinctrl-names = "default";
		gpio-controller;
		#gpio-cells = <2>;
		status = "disabled";
	};

	gpio6: gpio@49006000 {
		compatible = "snps,designware-gpio";
		reg = <0x49006000 0x1000>;
		ngpios = <8>;
		interrupts = <227 ALIF_DEFAULT_IRQ_PRIORITY>,
			     <228 ALIF_DEFAULT_IRQ_PRIORITY>,
			     <229 ALIF_DEFAULT_IRQ_PRIORITY>,
			     <230 ALIF_DEFAULT_IRQ_PRIORITY>,
			     <231 ALIF_DEFAULT_IRQ_PRIORITY>,
			     <232 ALIF_DEFAULT_IRQ_PRIORITY>,
			     <233 ALIF_DEFAULT_IRQ_PRIORITY>,
			     <234 ALIF_DEFAULT_IRQ_PRIORITY>;
		pinctrl-0 = < &pinctrl_gpio6 >;
		pinctrl-names = "default";
		gpio-controller;
		#gpio-cells = <2>;
		status = "disabled";
	};

	gpio7: gpio@49007000 {
		compatible = "snps,designware-gpio";
		reg = <0x49007000 0x1000>;
		ngpios = <8>;
		interrupts = <235 ALIF_DEFAULT_IRQ_PRIORITY>,
			     <236 ALIF_DEFAULT_IRQ_PRIORITY>,
			     <237 ALIF_DEFAULT_IRQ_PRIORITY>,
			     <238 ALIF_DEFAULT_IRQ_PRIORITY>,
			     <239 ALIF_DEFAULT_IRQ_PRIORITY>,
			     <240 ALIF_DEFAULT_IRQ_PRIORITY>,
			     <241 ALIF_DEFAULT_IRQ_PRIORITY>,
			     <242 ALIF_DEFAULT_IRQ_PRIORITY>;
		pinctrl-0 = < &pinctrl_gpio7 >;
		pinctrl-names = "default";
		gpio-controller;
		#gpio-cells = <2>;
		status = "disabled";
	};

	gpio8: gpio@49008000 {
		compatible = "snps,designware-gpio";
		reg = <0x49008000 0x1000>;
		ngpios = <8>;
		interrupts = <243 ALIF_DEFAULT_IRQ_PRIORITY>,
			     <244 ALIF_DEFAULT_IRQ_PRIORITY>,
			     <245 ALIF_DEFAULT_IRQ_PRIORITY>,
			     <246 ALIF_DEFAULT_IRQ_PRIORITY>,
			     <247 ALIF_DEFAULT_IRQ_PRIORITY>,
			     <248 ALIF_DEFAULT_IRQ_PRIORITY>,
			     <249 ALIF_DEFAULT_IRQ_PRIORITY>,
			     <250 ALIF_DEFAULT_IRQ_PRIORITY>;
		pinctrl-0 = < &pinctrl_gpio8 >;
		pinctrl-names = "default";
		gpio-controller;
		#gpio-cells = <2>;
		status = "disabled";
	};

	gpio9: gpio@49009000 {
		compatible = "snps,designware-gpio";
		reg = <0x49009000 0x1000>;
		ngpios = <8>;
		interrupts = <251 ALIF_DEFAULT_IRQ_PRIORITY>,
			     <252 ALIF_DEFAULT_IRQ_PRIORITY>,
			     <253 ALIF_DEFAULT_IRQ_PRIORITY>,
			     <254 ALIF_DEFAULT_IRQ_PRIORITY>,
			     <255 ALIF_DEFAULT_IRQ_PRIORITY>,
			     <256 ALIF_DEFAULT_IRQ_PRIORITY>,
			     <257 ALIF_DEFAULT_IRQ_PRIORITY>,
			     <258 ALIF_DEFAULT_IRQ_PRIORITY>;
		pinctrl-0 = < &pinctrl_gpio9 >;
		pinctrl-names = "default";
		gpio-controller;
		#gpio-cells = <2>;
		status = "disabled";
	};

	lpgpio: gpio@42002000 {
		compatible = "snps,designware-gpio";
		reg = <0x42002000 0x1000>;
		ngpios = <8>;
		interrupts = <171 ALIF_DEFAULT_IRQ_PRIORITY>,
			     <172 ALIF_DEFAULT_IRQ_PRIORITY>,
			     <173 ALIF_DEFAULT_IRQ_PRIORITY>,
			     <174 ALIF_DEFAULT_IRQ_PRIORITY>,
			     <175 ALIF_DEFAULT_IRQ_PRIORITY>,
			     <176 ALIF_DEFAULT_IRQ_PRIORITY>,
			     <177 ALIF_DEFAULT_IRQ_PRIORITY>,
			     <178 ALIF_DEFAULT_IRQ_PRIORITY>;
		pinctrl-0 = < &pinctrl_lpgpio >;
		pinctrl-names = "default";
		gpio-controller;
		#gpio-cells = <2>;
		status = "disabled";
	};

	crc0: crc0@48107000 {
		compatible = "alif,alif-crc";
		reg = <0x48107000 0x1000>;
		crc_algo = "CRC_8_BIT_SIZE";
		status = "disabled";
	};

	crc1: crc1@48108000 {
		compatible = "alif,alif-crc";
		reg = <0x48108000 0x1000>;
		crc_algo = "CRC_8_BIT_SIZE";
		status = "disabled";
	};

	pdm: pdm@4902d000 {
		compatible = "alif,alif-pdm";
		reg = <0x4902d000 0x1000>;
		interrupts = <145 ALIF_DEFAULT_IRQ_PRIORITY>,
			     <146 ALIF_DEFAULT_IRQ_PRIORITY>,
			     <147 ALIF_DEFAULT_IRQ_PRIORITY>;
		interrupt-names = "warning_intr",
				  "error_intr",
				  "audio_det_intr";
		pinctrl-0 = <&pinctrl_pdm0>;
		pinctrl-names = "default";
		clocks = <&clockctrl ALIF_PDM_76M8_CLK>;
		fifo_watermark = <5>;
		bypass_iir_filter = <1>;
		status = "disabled";
	};

	adc0: adc0@49020000{
		compatible = "alif,adc";
		reg =	<0x49020000 0x1000>,
			<0x49020000 0x100>,
			<0x49023000 0x100>,
			<0x1A604000 0x100>;
		reg-names = "adc_reg", "analog_reg", "comp_reg", "aon_regs";

		comparator_threshold_a = <0x01>;
		comparator_threshold_b = <0x01>;
		comparator_threshold_comparison = "ABOVE_THRESHOLD_A_AND_B";
		interrupts		= <(ADC_DONE0_INTERRUPT | ADC_DONE1_INTERRUPT)>;

		sample-width		= <16>;
		clock_div		= <2>;
		avg_sample_num		= <256>;
		shift_n_bits		= <8>;
		shift_direction		= "RIGHT_SHIFT";
		comparator_bias		= "2.5_MS/s";
		driver_instance		= "ADC_INSTANCE_ADC12_0";
		adc_channel_scan	= "SINGLE_CHANNEL_SCAN";
		adc_conversion_mode	= "SINGLE_SHOT_CONVERSION";
		/* pga_enable; */       /* This property is valid in differential mode only */
		pga_gain		= "ADC_PGA_GAIN_0_DB";
		pinctrl-0		= < &pinctrl_adc0 >;
		pinctrl-names		= "default";
		interrupts		= <151 0>,
					  <154 0>,
					  <157 0>,
					  <160 0>;
		interrupt-names         = "done0",
					  "done1",
					  "comp_a",
					  "comp_b";
		status = "disabled";
	};

	adc1: adc1@49021000{
		compatible = "alif,adc";
		reg =	<0x49021000 0x1000>,
			<0x49020000 0x100>,
			<0x49023000 0x100>,
			<0x1A604000 0x100>;
		reg-names = "adc_reg", "analog_reg", "comp_reg", "aon_regs";

		comparator_threshold_a = <0x01>;
		comparator_threshold_b = <0x01>;
		comparator_threshold_comparison = "ABOVE_THRESHOLD_A_AND_B";
		interrupts		= <(ADC_DONE0_INTERRUPT | ADC_DONE1_INTERRUPT)>;

		sample-width		= <16>;
		clock_div		= <2>;
		avg_sample_num		= <256>;
		shift_n_bits		= <8>;
		shift_direction		= "RIGHT_SHIFT";
		comparator_bias		= "2.5_MS/s";
		driver_instance		= "ADC_INSTANCE_ADC12_1";
		adc_channel_scan	= "SINGLE_CHANNEL_SCAN";
		adc_conversion_mode	= "SINGLE_SHOT_CONVERSION";
		/* pga_enable; */       /* This property is valid in differential mode only */
		pga_gain		= "ADC_PGA_GAIN_0_DB";
		pinctrl-0		= < &pinctrl_adc1 >;
		pinctrl-names		= "default";
		interrupts		= <152 0>,
					  <155 0>,
					  <158 0>,
					  <161 0>;
		interrupt-names		= "done0",
					  "done1",
					  "comp_a",
					  "comp_b";
		status = "disabled";
	};

	adc2: adc2@49022000{
		compatible = "alif,adc";
		reg =	<0x49022000 0x1000>,
			<0x49020000 0x100>,
			<0x49023000 0x100>,
			<0x1A604000 0x100>;
		reg-names = "adc_reg", "analog_reg", "comp_reg", "aon_regs";

		comparator_threshold_a = <0x01>;
		comparator_threshold_b = <0x01>;
		comparator_threshold_comparison = "ABOVE_THRESHOLD_A_AND_B";
		interrupts              = <(ADC_DONE0_INTERRUPT | ADC_DONE1_INTERRUPT)>;

		sample-width		= <16>;
		clock_div		= <2>;
		avg_sample_num		= <256>;
		shift_n_bits		= <8>;
		shift_direction		= "RIGHT_SHIFT";
		comparator_bias		= "2.5_MS/s";
		driver_instance		= "ADC_INSTANCE_ADC12_2";
		adc_channel_scan	= "SINGLE_CHANNEL_SCAN";
		adc_conversion_mode	= "SINGLE_SHOT_CONVERSION";
		/* pga_enable; */       /* This property is valid in differential mode only */
		pga_gain		= "ADC_PGA_GAIN_0_DB";
		pinctrl-0		= < &pinctrl_adc2 >;
		pinctrl-names		= "default";
		interrupts		= <153 0>,
					  <156 0>,
					  <159 0>,
					  <162 0>;
		interrupt-names		= "done0",
					  "done1",
					  "comp_a",
					  "comp_b";
		status = "disabled";
	};

	adc24: adc24@49027000{
		compatible = "alif,adc";
		reg =	<0x49027000 0x1000>,
			<0x49020000 0x100>,
			<0x49023000 0x100>,
			<0x1A604000 0x100>;
		reg-names = "adc_reg", "analog_reg", "comp_reg", "aon_regs";

		comparator_threshold_a = <0x01>;
		comparator_threshold_b = <0x01>;
		comparator_threshold_comparison = "ABOVE_THRESHOLD_A_AND_B";
		interrupts              = <(ADC_DONE0_INTERRUPT | ADC_DONE1_INTERRUPT)>;

		clock_div		= <2>;
		avg_sample_num		= <256>;
		shift_n_bits		= <8>;
		shift_direction		= "RIGHT_SHIFT";
		adc24_output_rate	= "1KS/s";
		adc24_bias		= "8.75uA";
		driver_instance		= "ADC_INSTANCE_ADC24_0";
		adc_channel_scan	= "SINGLE_CHANNEL_SCAN";
		adc_conversion_mode	= "SINGLE_SHOT_CONVERSION";
		/* pga_enable; */       /* This property is valid in differential mode only */
		pga_gain		= "ADC_PGA_GAIN_0_DB";
		pinctrl-0		= < &pinctrl_adc24 >;
		pinctrl-names		= "default";
		interrupts		= <163 3>,
					  <164 3>,
					  <165 3>,
					  <166 3>;
		interrupt-names		= "done0",
					  "done1",
					  "comp_a",
					  "comp_b";
		status = "disabled";
	};

	i2c0: i2c0@49010000 {
		compatible = "snps,designware-i2c";
		clock-frequency = <I2C_BITRATE_STANDARD>;
		/*
		 * For Standard  speed LCNT=0 and HCNT=0
		 * For Fast      speed LCNT=50 and HCNT=30
		 * For Fast Plus speed LCNT=35 and HCNT=5
		 */
		hcnt-offset = <0>;
		lcnt-offset = <0>;
		#address-cells = <1>;
		#size-cells = <0>;
		reg = <0x49010000 0x1000>;
		pinctrl-0 = < &pinctrl_i2c0 >;
		pinctrl-names = "default";
		interrupt-parent = <&nvic>;
		interrupts = <132 ALIF_DEFAULT_IRQ_PRIORITY>;
		tx_threshold = <16>;
		rx_threshold = <0>;
		status = "disabled";
	};

	i2c1: i2c1@49011000 {
		compatible = "snps,designware-i2c";
		clock-frequency = <I2C_BITRATE_STANDARD>;
		/*
		 * For Standard  speed LCNT=0 and HCNT=0
		 * For Fast      speed LCNT=50 and HCNT=30
		 * For Fast Plus speed LCNT=35 and HCNT=5
		 */
		hcnt-offset = <0>;
		lcnt-offset = <0>;
		#address-cells = <1>;
		#size-cells = <0>;
		reg = <0x49011000 0x1000>;
		pinctrl-0 = < &pinctrl_i2c1 >;
		pinctrl-names = "default";
		interrupt-parent = <&nvic>;
		interrupts = <133 ALIF_DEFAULT_IRQ_PRIORITY>;
		tx_threshold = <16>;
		rx_threshold = <0>;
		status = "disabled";
	};

	lpi2c0: lpi2c0@43009000 {
		compatible = "alif,lpi2c";
		#address-cells = <1>;
		#size-cells = <0>;
		pinctrl-names = "default";
		pinctrl-0 = <&pinctrl_lpi2c0>;
		reg = <0x43009000 0x100>;
		interrupts = <47 ALIF_DEFAULT_IRQ_PRIORITY>;
		status = "disabled";
	};

	i3c0: i3c0@49034000 {
		compatible      = "snps,designware-i3c";
		#address-cells  = <3>;
		#size-cells     = <0>;
		reg             = <0x49034000 0x1000>;
		interrupt-parent= <&nvic>;
		interrupts      = <136 0>;
		clocks          = <&clockctrl ALIF_I3C_CLK>;
		pinctrl-0       = <&pinctrl_i3c0>;
		pinctrl-names   = "default";
		i3c-scl-hz      = <10000000>;
		i2c-scl-hz      = <400000>;
		status          = "disabled";
	};

	i2s0: i2s0@49014000 {
		compatible = "snps,designware-i2s";
		clock-frequency = <76800000>;
		driver-instance	= "I2S_INSTANCE_0";
		reg = <0x49014000 0x1000>;
		pinctrl-names = "default";
		pinctrl-0 = <&pinctrl_i2s0>;
		interrupts = <141 ALIF_DEFAULT_IRQ_PRIORITY>;
		status = "disabled";
	};

	i2s1: i2s1@49015000 {
		compatible = "snps,designware-i2s";
		clock-frequency = <76800000>;
		driver-instance	= "I2S_INSTANCE_1";
		reg = <0x49015000 0x1000>;
		pinctrl-names = "default";
		pinctrl-0 = <&pinctrl_i2s1>;
		interrupts = <142 ALIF_DEFAULT_IRQ_PRIORITY>;
		status = "disabled";
	};

	i2s4: lpi2s@43001000 {
		compatible = "snps,designware-i2s";
		clock-frequency = <76800000>;
		driver-instance	= "I2S_INSTANCE_4";
		reg = <0x43001000 0x1000>;
		pinctrl-names = "default";
		pinctrl-0 = <&pinctrl_lpi2s>;
		interrupts = <48 ALIF_DEFAULT_IRQ_PRIORITY>;
		status = "disabled";
	};

	ospi0: ospi0@83000000 {
		compatible = "snps,designware-ospi";
		reg = <0x83000000 0x1000>;
		pinctrl-0 = <&pinctrl_ospi0>;
		pinctrl-names = "default";
		interrupt-parent = <&nvic>;
		interrupts = <96 ALIF_DEFAULT_IRQ_PRIORITY>;
		aes-reg = <0x83001000 0x100>;
		cs-pin = <0>;
		status = "disabled";
	};

	cdc200: cdc200@49031000 {
		compatible = "tes,cdc-2.1";
		reg = <0x49031000 0x1000>;
		status = "okay";
		interrupts =	<333 0>,
				<334 0>,
				<335 0>,
				<336 0>,
				<337 0>,
				<338 0>,
				<339 0>,
				<340 0>,
				<341 0>,
				<342 0>;
		interrupt-names = "scanline_0",
				  "scanline_1",
				  "fifo_warning_0",
				  "fifo_warning_1",
				  "fifo_underrun_0",
				  "fifo_underrun_1",
				  "bus_error_0",
				  "bus_error_1",
				  "reg_reload_0",
				  "reg_reload_1";
		pinctrl-0 = < &pinctrl_cdc200 >;
		pinctrl-names = "default";

		clocks = <&clockctrl ALIF_DPI_CLK>, <&clockctrl ALIF_CDC200_PIX_SYST_ACLK>;
		clock-names = "dpi-clk-en", "pixel-clk";

		/* Panel Config */
		width = <800>;
		height = <480>;
		hfront-porch = <210>;
		hback-porch = <46>;
		hsync-len = <1>;
		vfront-porch = <22>;
		vback-porch = <23>;
		vsync-len = <1>;
		hsync-active = <0>;
		vsync-active = <0>;
		de-active = <1>;
		pixelclk-active = <0>;
		clock-frequency = <2779910>;
		/* BG Layer color is 24-bit in size. */
		bg-color = <0x5a5a5a>;

		/* Layer 0 Config */
		enable-l1 = <1>;
		pixel-fmt-l1 = "rgb-565";
		/* Default color for Layer is 32-bit in size. */
		def-back-color-l1 = <0x00ff00>;
		win-x0-l1 = <0>;
		win-y0-l1 = <0>;
		win-x1-l1 = <300>;
		win-y1-l1 = <480>;
		blend-factor1-l1 = <4>;
		blend-factor2-l1 = <5>;
		const-alpha-l1 = <0x7f>;

		/* Layer 1 Config */
		enable-l2 = <1>;
		pixel-fmt-l2 = "argb-8888";
		win-x0-l2 = <500>;
		win-y0-l2 = <0>;
		win-x1-l2 = <800>;
		win-y1-l2 = <68>;
		blend-factor1-l2 = <4>;
		blend-factor2-l2 = <5>;
		const-alpha-l2 = <0xaf>;
	};

	mipi_dsi: mipi-dsi@49032000 {
		#address-cells = <1>;
		#size-cells = <0>;
		compatible = "snps,designware-dsi";
		reg = <0x49032000 0x1000>;
		interrupts = <343 0>;
		cdc-if = <&cdc200>;
		phy-if = <&dphy>;

		clocks = <&clockctrl ALIF_DSI_CLK>, <&clockctrl ALIF_CDC200_PIX_SYST_ACLK>,
			<&clockctrl ALIF_MIPI_TXDPHY_CLK>;
		clock-names = "dsi-clk-en", "pixel-clk", "tx-dphy-clk";
		dpi-shutdn-active = <1>;
		dpi-colorm-active = <1>;
		vid-pkt-size = <480>;
		ecc-recv-en;
		crc-recv-en;
		frame-ack-en;
		status = "disabled";

		mw405: mw405@0 {
			status = "okay";
			compatible = "focuslcd,mw405";
			reg = <0>;
			reset-gpios = <&lpgpio 5 GPIO_ACTIVE_HIGH>;
			bl-gpios = <&gpio6 1 GPIO_ACTIVE_HIGH>;
			data-lanes = <2>;
			width = <480>;
			height = <800>;
			video-mode = "burst";
			command-tx-mode = "high-speed";
			pixel-format = <MIPI_DSI_PIXFMT_RGB888>;
			status = "okay";
		};
	};

	dphy: d-phy@4903f000{
		compatible = "snps,designware-dphy";
		reg = <0x4903f000 0x40>,
		      <0x49032000 0x1000>,
		      <0x49033000 0x1000>;
		reg-names = "expmst_reg", "dsi_reg", "csi_reg";

		clocks = <&clockctrl ALIF_MIPI_PLLREF_CLK>;
		clock-names = "pllref-clk";

		ref-frequency = <38400000>;
		cfg-clk-frequency = <25000000>;
		status = "okay";
	};
};

&{/} {
	se_service: se_service {
		compatible = "alif,secure-enclave-services";
		mhuv2-send-node = <&seservice0s>;
		mhuv2-recv-node = <&seservice0r>;
		status = "okay";
	};

	rng: rng {
		status = "okay";
		compatible = "alif,secure-enclave-trng";
	};

	clocks {
		lfrc: lfrc {
			compatible = "fixed-clock";
			clock-frequency = <32000>;
			status = "okay";
			#clock-cells = <0>;
		};

		lfxo: lfxo {
			compatible = "fixed-clock";
			clock-frequency = <32768>;
			status = "okay";
			#clock-cells = <0>;
		};

		hfrc: hfrc {
			compatible = "fixed-clock";
			clock-frequency = <76800000>;
			status = "okay";
			#clock-cells = <0>;
		};

		hfxo: hfxo {
			compatible = "fixed-clock";
			clock-frequency = <38400000>;
			status = "okay";
			#clock-cells = <0>;
		};

		pll_clk1: pll_clk1 {
			compatible = "alif,clock";
			clock-frequency = <800000000>;
			status = "okay";
			#clock-cells = <0>;
		};

		syst_aclk: axi_clk {
			compatible = "alif,clock";
			clock-frequency = <400000000>;
			status = "okay";
			#clock-cells = <0>;
		};

		syst_hclk: ahb_clk {
			compatible = "alif,clock";
			clock-frequency = <200000000>;
			status = "okay";
			#clock-cells = <0>;
		};
	};

	aliases {
		mipi-dsi = &mipi_dsi;
		panel = &mw405;
	};

	chosen {
		zephyr,entropy = &rng;
		zephyr,flash-controller = &mram_flash;
		zephyr,display = &cdc200;
	};
};
